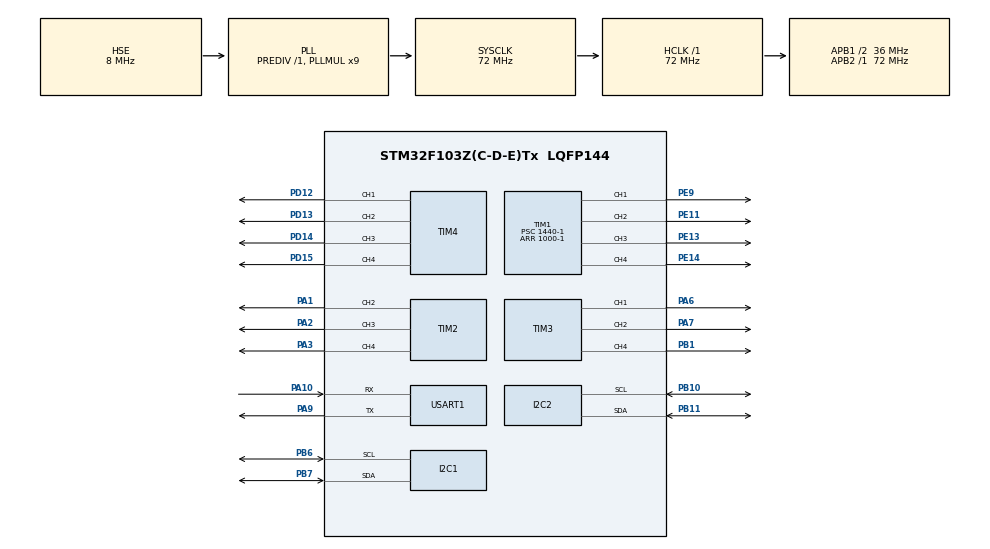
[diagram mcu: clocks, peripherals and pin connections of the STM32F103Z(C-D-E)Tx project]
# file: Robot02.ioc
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Dma.I2C2_RX.0.Direction=DMA_PERIPH_TO_MEMORY
Dma.I2C2_RX.0.Instance=DMA1_Channel5
Dma.I2C2_RX.0.MemDataAlignment=DMA_MDATAALIGN_BYTE
Dma.I2C2_RX.0.MemInc=DMA_MINC_ENABLE
Dma.I2C2_RX.0.Mode=DMA_CIRCULAR
Dma.I2C2_RX.0.PeriphDataAlignment=DMA_PDATAALIGN_BYTE
Dma.I2C2_RX.0.PeriphInc=DMA_PINC_DISABLE
Dma.I2C2_RX.0.Priority=DMA_PRIORITY_LOW
Dma.I2C2_TX.1.Direction=DMA_MEMORY_TO_PERIPH
Dma.I2C2_TX.1.Instance=DMA1_Channel4
Dma.I2C2_TX.1.MemDataAlignment=DMA_MDATAALIGN_BYTE
Dma.I2C2_TX.1.MemInc=DMA_MINC_ENABLE
Dma.I2C2_TX.1.Mode=DMA_CIRCULAR
Dma.I2C2_TX.1.PeriphDataAlignment=DMA_PDATAALIGN_BYTE
Dma.I2C2_TX.1.PeriphInc=DMA_PINC_DISABLE
Dma.I2C2_TX.1.Priority=DMA_PRIORITY_LOW
Dma.Request0=I2C2_RX
Dma.Request1=I2C2_TX
Mcu.Family=STM32F1
Mcu.Name=STM32F103Z(C-D-E)Tx
Mcu.Package=LQFP144
NVIC.DMA1_Channel4_IRQn=true\:0\:0\:false\:false\:true\:false\:true\:true
NVIC.DMA1_Channel5_IRQn=true\:0\:0\:false\:false\:true\:false\:true\:true
NVIC.PriorityGroup=NVIC_PRIORITYGROUP_4
NVIC.TIM7_IRQn=true\:0\:0\:false\:false\:true\:true\:true\:true
NVIC.USART1_IRQn=true\:0\:0\:false\:false\:true\:true\:true\:true
OSC_IN.Mode=HSE-External-Oscillator
OSC_IN.Signal=RCC_OSC_IN
OSC_OUT.Mode=HSE-External-Oscillator
OSC_OUT.Signal=RCC_OSC_OUT
PA1.Signal=S_TIM2_CH2
PA10.Mode=Asynchronous
PA10.Signal=USART1_RX
PA13.Mode=Serial_Wire
PA13.Signal=SYS_JTMS-SWDIO
PA14.Mode=Serial_Wire
PA14.Signal=SYS_JTCK-SWCLK
PA2.Signal=S_TIM2_CH3
PA3.Signal=S_TIM2_CH4
PA6.Signal=S_TIM3_CH1
PA7.Signal=S_TIM3_CH2
PA9.Mode=Asynchronous
PA9.Signal=USART1_TX
PB1.Signal=S_TIM3_CH4
PB10.Mode=I2C
PB10.Signal=I2C2_SCL
PB11.Mode=I2C
PB11.Signal=I2C2_SDA
PB6.Mode=I2C
PB6.Signal=I2C1_SCL
PB7.Mode=I2C
PB7.Signal=I2C1_SDA
PD12.Signal=S_TIM4_CH1
PD13.Signal=S_TIM4_CH2
PD14.Signal=S_TIM4_CH3
PD15.Signal=S_TIM4_CH4
PE11.Signal=S_TIM1_CH2
PE13.Signal=S_TIM1_CH3
PE14.Signal=S_TIM1_CH4
PE9.Signal=S_TIM1_CH1
ProjectManager.HeapSize=0x200
ProjectManager.StackSize=0x400
ProjectManager.TargetToolchain=STM32CubeIDE
RCC.AHBFreq_Value=72000000
RCC.APB1CLKDivider=RCC_HCLK_DIV2
RCC.APB1Freq_Value=36000000
RCC.APB1TimFreq_Value=72000000
RCC.APB2Freq_Value=72000000
RCC.APB2TimFreq_Value=72000000
RCC.HCLKFreq_Value=72000000
RCC.PLLMUL=RCC_PLL_MUL9
RCC.PLLSourceVirtual=RCC_PLLSOURCE_HSE
RCC.SYSCLKFreq_VALUE=72000000
RCC.SYSCLKSource=RCC_SYSCLKSOURCE_PLLCLK
RCC.USBFreq_Value=72000000
SH.S_TIM1_CH1.0=TIM1_CH1,PWM Generation1 CH1
SH.S_TIM1_CH2.0=TIM1_CH2,PWM Generation2 CH2
SH.S_TIM1_CH3.0=TIM1_CH3,PWM Generation3 CH3
SH.S_TIM1_CH4.0=TIM1_CH4,PWM Generation4 CH4
SH.S_TIM2_CH2.0=TIM2_CH2,PWM Generation2 CH2
SH.S_TIM2_CH3.0=TIM2_CH3,PWM Generation3 CH3
SH.S_TIM2_CH4.0=TIM2_CH4,PWM Generation4 CH4
SH.S_TIM3_CH1.0=TIM3_CH1,PWM Generation1 CH1
SH.S_TIM3_CH2.0=TIM3_CH2,PWM Generation2 CH2
SH.S_TIM3_CH4.0=TIM3_CH4,PWM Generation4 CH4
SH.S_TIM4_CH1.0=TIM4_CH1,PWM Generation1 CH1
SH.S_TIM4_CH2.0=TIM4_CH2,PWM Generation2 CH2
SH.S_TIM4_CH3.0=TIM4_CH3,PWM Generation3 CH3
SH.S_TIM4_CH4.0=TIM4_CH4,PWM Generation4 CH4
TIM1.Channel-PWM\ Generation1\ CH1=TIM_CHANNEL_1
TIM1.Channel-PWM\ Generation2\ CH2=TIM_CHANNEL_2
TIM1.Channel-PWM\ Generation3\ CH3=TIM_CHANNEL_3
TIM1.Channel-PWM\ Generation4\ CH4=TIM_CHANNEL_4
TIM1.Period=1000-1
TIM1.Prescaler=1440-1
TIM2.Channel-PWM\ Generation2\ CH2=TIM_CHANNEL_2
TIM2.Channel-PWM\ Generation3\ CH3=TIM_CHANNEL_3
TIM2.Channel-PWM\ Generation4\ CH4=TIM_CHANNEL_4
TIM3.Channel-PWM\ Generation1\ CH1=TIM_CHANNEL_1
TIM3.Channel-PWM\ Generation2\ CH2=TIM_CHANNEL_2
TIM3.Channel-PWM\ Generation4\ CH4=TIM_CHANNEL_4
TIM4.Channel-PWM\ Generation1\ CH1=TIM_CHANNEL_1
TIM4.Channel-PWM\ Generation2\ CH2=TIM_CHANNEL_2
TIM4.Channel-PWM\ Generation3\ CH3=TIM_CHANNEL_3
TIM4.Channel-PWM\ Generation4\ CH4=TIM_CHANNEL_4
TIM7.AutoReloadPreload=TIM_AUTORELOAD_PRELOAD_ENABLE
TIM7.Period=1000
TIM7.Prescaler=71
USART1.VirtualMode=VM_ASYNC
VP_TIM7_VS_ClockSourceINT.Mode=Enable_Timer
board=custom

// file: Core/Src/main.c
/* USER CODE BEGIN Header */
/**
  ******************************************************************************
  * @file           : main.c
  * @brief          : Main program body
  ******************************************************************************
  * @attention
  *
  * Copyright (c) 2022 STMicroelectronics.
  * All rights reserved.
  *
  * This software is licensed under terms that can be found in the LICENSE file
  * in the root directory of this software component.
  * If no LICENSE file comes with this software, it is provided AS-IS.
  *
  ******************************************************************************
  */
/* USER CODE END Header */
#include <stdio.h>
#include "main.h"
#include "dma.h"
#include "i2c.h"
#include "tim.h"
#include "usart.h"
#include "gpio.h"

/* USER CODE BEGIN Includes */
#ifdef __GNUC__
#define PUTCHAR_PROTOTYPE int __io_putchar(int ch)
#else
#define PUTCHAR_PROTOTYPE int fputc(int ch, FILE *f)
#endif
PUTCHAR_PROTOTYPE
{
    HAL_UART_Transmit(&huart1, (uint8_t*)&ch,1,HAL_MAX_DELAY);
    return ch;
}

/* USER CODE END Includes */

/* USER CODE BEGIN PV */
static void MPU6050_Init(void);
/* USER CODE END PV */

void SystemClock_Config(void);

/* USER CODE BEGIN 0 */

static double p_last = 0;
static double x_last = 0;
/* USER CODE END 0 */

//过程噪音   买的破温度计有多破。。
#define P_Q 0.1
//测量噪声
#define M_R 0.03

float kalmanFilter_A(float inData)
{
    static float prevData=0;
    //其中p的初值可以随便取，但是不能为0（为0的话卡尔曼滤波器就认为已经是最优滤波器了）
    static float p=0.01, q=P_Q, r=M_R, kGain=0;
    p = p+q;
    kGain = p/(p+r);

    inData = prevData+(kGain*(inData-prevData));
    p = (1-kGain)*p;

    prevData = inData;

    return inData;
}

int main(void)
{

  /* MCU Configuration--------------------------------------------------------*/

  /* Reset of all peripherals, Initializes the Flash interface and the Systick. */
  HAL_Init();

  /* Configure the system clock */
  SystemClock_Config();

  /* Initialize all configured peripherals */
  MX_GPIO_Init();
  MX_TIM1_Init();
  MX_TIM2_Init();
  MX_TIM3_Init();
  MX_TIM4_Init();
  MX_TIM7_Init();
  MX_USART1_UART_Init();
  MX_DMA_Init();
  MX_I2C2_Init();
  MX_I2C1_Init();
  /* USER CODE BEGIN 2 */
    mainApp();

  /* USER CODE END 2 */

  /* Infinite loop */
  while (1)
  {
  }
}

void SystemClock_Config(void)
{
  RCC_OscInitTypeDef RCC_OscInitStruct = {0};
  RCC_ClkInitTypeDef RCC_ClkInitStruct = {0};

  /** Initializes the RCC Oscillators according to the specified parameters
  * in the RCC_OscInitTypeDef structure.
  */
  RCC_OscInitStruct.OscillatorType = RCC_OSCILLATORTYPE_HSE;
  RCC_OscInitStruct.HSEState = RCC_HSE_ON;
  RCC_OscInitStruct.HSEPredivValue = RCC_HSE_PREDIV_DIV1;
  RCC_OscInitStruct.HSIState = RCC_HSI_ON;
  RCC_OscInitStruct.PLL.PLLState = RCC_PLL_ON;
  RCC_OscInitStruct.PLL.PLLSource = RCC_PLLSOURCE_HSE;
  RCC_OscInitStruct.PLL.PLLMUL = RCC_PLL_MUL9;
  if (HAL_RCC_OscConfig(&RCC_OscInitStruct) != HAL_OK)
  {
    Error_Handler();
  }

  /** Initializes the CPU, AHB and APB buses clocks
  */
  RCC_ClkInitStruct.ClockType = RCC_CLOCKTYPE_HCLK|RCC_CLOCKTYPE_SYSCLK
                              |RCC_CLOCKTYPE_PCLK1|RCC_CLOCKTYPE_PCLK2;
  RCC_ClkInitStruct.SYSCLKSource = RCC_SYSCLKSOURCE_PLLCLK;
  RCC_ClkInitStruct.AHBCLKDivider = RCC_SYSCLK_DIV1;
  RCC_ClkInitStruct.APB1CLKDivider = RCC_HCLK_DIV2;
  RCC_ClkInitStruct.APB2CLKDivider = RCC_HCLK_DIV1;

  if (HAL_RCC_ClockConfig(&RCC_ClkInitStruct, FLASH_LATENCY_2) != HAL_OK)
  {
    Error_Handler();
  }
}

void Error_Handler(void)
{
  __disable_irq();
  while (1)
  {
  }
}
